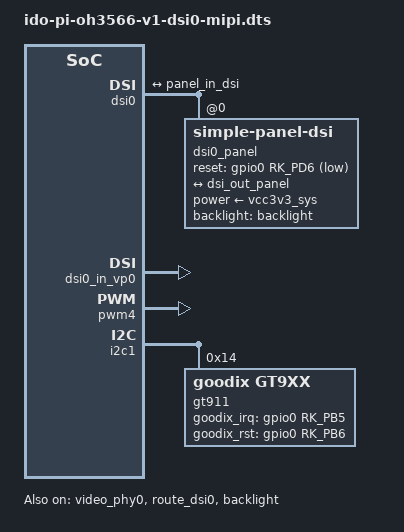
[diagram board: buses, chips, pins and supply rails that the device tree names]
// SPDX-License-Identifier: (GPL-2.0+ OR MIT)
/*
 * Copyright (c) 2020 Rockchip Electronics Co., Ltd.
 *
 */

/dts-v1/;

#include "ido-pi-oh3566-v1.dtsi"

&video_phy0 {
	status = "okay";
};

/*
 * video_phy0 needs to be enabled
 * when dsi0 is enabled
 */
&dsi0 {
	status = "okay";
	//rockchip,lane-rate = <1000>;
	dsi0_panel: panel@0 {
		status = "okay";
		compatible = "simple-panel-dsi";
		reg = <0>;
		backlight = <&backlight>;
		reset-delay-ms = <60>;
		enable-delay-ms = <60>;
		prepare-delay-ms = <60>;
		init-delay-ms = <60>;
		unprepare-delay-ms = <60>;
		disable-delay-ms = <60>;
		dsi,flags = <(MIPI_DSI_MODE_VIDEO | MIPI_DSI_MODE_VIDEO_BURST |
			MIPI_DSI_MODE_LPM | MIPI_DSI_MODE_EOT_PACKET)>;
		dsi,format = <MIPI_DSI_FMT_RGB888>;
		dsi,lanes  = <4>;
		panel-init-sequence = [
			29 00 04 FF 98 81 03 
			29 00 02 01 00 
			29 00 02 02 00 
			29 00 02 03 73 
			29 00 02 04 13 
			29 00 02 05 00 
			29 00 02 06 0A 
			29 00 02 07 05 
			29 00 02 08 00 
			29 00 02 09 28 
			29 00 02 0a 00 
			29 00 02 0b 00 
			29 00 02 0c 00 
			29 00 02 0d 28 
			29 00 02 0e 00 
			29 00 02 0f 28 
			29 00 02 10 28 
			29 00 02 11 00 
			29 00 02 12 00 
			29 00 02 13 00 
			29 00 02 14 00 
			29 00 02 15 00 
			29 00 02 16 00 
			29 00 02 17 00 
			29 00 02 18 00 
			29 00 02 19 00 
			29 00 02 1a 00 
			29 00 02 1b 00 
			29 00 02 1c 00 
			29 00 02 1d 00 
			29 00 02 1e 40 
			29 00 02 1f 80 
			29 00 02 20 06 
			29 00 02 21 01 
			29 00 02 22 00 
			29 00 02 23 00 
			29 00 02 24 00 
			29 00 02 25 00 
			29 00 02 26 00 
			29 00 02 27 00 
			29 00 02 28 33 
			29 00 02 29 33 
			29 00 02 2a 00 
			29 00 02 2b 00 
			29 00 02 2c 04 
			29 00 02 2d 04 
			29 00 02 2e 05 
			29 00 02 2f 05 
			29 00 02 30 00 
			29 00 02 31 00 
			29 00 02 32 31 
			29 00 02 33 00 
			29 00 02 34 00 
			29 00 02 35 0A 
			29 00 02 36 00 
			29 00 02 37 08 
			29 00 02 38 00 
			29 00 02 39 00 
			29 00 02 3a 00 
			29 00 02 3b 00 
			29 00 02 3c 00 
			29 00 02 3d 00 
			29 00 02 3e 00 
			29 00 02 3f 00 
			29 00 02 40 00 
			29 00 02 41 00 
			29 00 02 42 00 
			29 00 02 43 08 
			29 00 02 44 00 
			29 00 02 50 01 
			29 00 02 51 23 
			29 00 02 52 44 
			29 00 02 53 67 
			29 00 02 54 89 
			29 00 02 55 ab 
			29 00 02 56 01 
			29 00 02 57 23 
			29 00 02 58 45 
			29 00 02 59 67 
			29 00 02 5a 89 
			29 00 02 5b ab 
			29 00 02 5c cd 
			29 00 02 5d ef 
			29 00 02 5e 11 
			29 00 02 5f 02 
			29 00 02 60 08 
			29 00 02 61 0E 
			29 00 02 62 0F 
			29 00 02 63 0C 
			29 00 02 64 0D 
			29 00 02 65 17 
			29 00 02 66 01 
			29 00 02 67 01 
			29 00 02 68 02 
			29 00 02 69 02 
			29 00 02 6a 00 
			29 00 02 6b 00 
			29 00 02 6c 02 
			29 00 02 6d 02 
			29 00 02 6e 16 
			29 00 02 6f 16 
			29 00 02 70 06 
			29 00 02 71 06 
			29 00 02 72 07 
			29 00 02 73 07 
			29 00 02 74 02 
			29 00 02 75 02 
			29 00 02 76 08 
			29 00 02 77 0E 
			29 00 02 78 0F 
			29 00 02 79 0C 
			29 00 02 7a 0D 
			29 00 02 7b 17 
			29 00 02 7c 01 
			29 00 02 7d 01 
			29 00 02 7e 02 
			29 00 02 7f 02 
			29 00 02 80 00 
			29 00 02 81 00 
			29 00 02 82 02 
			29 00 02 83 02 
			29 00 02 84 16 
			29 00 02 85 16 
			29 00 02 86 06 
			29 00 02 87 06 
			29 00 02 88 07 
			29 00 02 89 07 
			29 00 02 8A 02 
			29 00 04 FF 98 81 04 
			29 00 02 6E 1A 
			29 00 02 6F 37 
			29 00 02 3A A4 
			29 00 02 8D 1F 
			29 00 02 87 BA 
			29 00 02 B2 D1 
			29 00 02 88 0B 
			29 00 02 38 01 
			29 00 02 39 00 
			29 00 02 B5 02 
			29 00 02 31 25 
			29 00 02 3B 98 
			29 00 04 FF 98 81 01 
			29 00 02 22 0A 
			29 00 02 31 00 
			29 00 02 53 5A 
			29 00 02 55 3D 
			29 00 02 50 9E 
			29 00 02 51 99 
			29 00 02 60 06 
			29 00 02 62 20 
			29 00 02 A0 00 
			29 00 02 A1 17 
			29 00 02 A2 26 
			29 00 02 A3 13 
			29 00 02 A4 16 
			29 00 02 A5 29 
			29 00 02 A6 1E 
			29 00 02 A7 1F 
			29 00 02 A8 8B 
			29 00 02 A9 1D 
			29 00 02 AA 2A 
			29 00 02 AB 7B 
			29 00 02 AC 1A 
			29 00 02 AD 19 
			29 00 02 AE 4E 
			29 00 02 AF 24 
			29 00 02 B0 29 
			29 00 02 B1 4F 
			29 00 02 B2 5C 
			29 00 02 B3 23 
			29 00 02 C0 00 
			29 00 02 C1 17 
			29 00 02 C2 26 
			29 00 02 C3 13 
			29 00 02 C4 16 
			29 00 02 C5 29 
			29 00 02 C6 1E 
			29 00 02 C7 1F 
			29 00 02 C8 8B 
			29 00 02 C9 1D 
			29 00 02 CA 2A 
			29 00 02 CB 7B 
			29 00 02 CC 1A 
			29 00 02 CD 19 
			29 00 02 CE 4E 
			29 00 02 CF 24 
			29 00 02 D0 29 
			29 00 02 D1 4F 
			29 00 02 D2 5C 
			29 00 02 D3 23
			29 00 04 FF 98 81 00 
			29 00 02 35 00
			05 78 01 11
			05 14 01 29
		];

		panel-exit-sequence = [
			05 00 01 28
			05 78 01 10
		];

		disp_timings0: display-timings {
			native-mode = <&dsi0_timing2>;
			dsi0_timing0: timing0 {
				clock-frequency = <148000000>;
				hactive = <1200>;
				vactive = <1920>;
				hback-porch = <130>;	
				hfront-porch = <160>;
				vback-porch = <16>;
				vfront-porch = <16>;
				hsync-len = <4>;
				vsync-len = <2>;
				hsync-active = <0>;
				vsync-active = <0>;
				de-active = <0>;
				pixelclk-active = <0>;
			};
			dsi0_timing1: timing1 {
				clock-frequency = <132000000>;
				hactive = <1080>;
				vactive = <1920>;
				hfront-porch = <15>;
				hsync-len = <2>;
				hback-porch = <30>;
				vfront-porch = <15>;
				vsync-len = <2>;
				vback-porch = <15>;
				hsync-active = <0>;
				vsync-active = <0>;
				de-active = <0>;
				pixelclk-active = <1>;
			};
			dsi0_timing2: timing2 {
				clock-frequency = <73400000>;
				hactive = <800>;
				vactive = <1280>;
				hfront-porch = <52>;
				hsync-len = <4>;
				hback-porch = <12>;
				vfront-porch = <60>;
				vsync-len = <18>;
				vback-porch = <50>;
				hsync-active = <0>;
				vsync-active = <0>;
				de-active = <0>;
				pixelclk-active = <1>;
			};
		};

		ports {
			#address-cells = <1>;
			#size-cells = <0>;

			port@0 {
				reg = <0>;
				panel_in_dsi: endpoint {
					remote-endpoint = <&dsi_out_panel>;
				};
			};
		};
	};

	ports {
		#address-cells = <1>;
		#size-cells = <0>;

		port@1 {
			reg = <1>;
			dsi_out_panel: endpoint {
				remote-endpoint = <&panel_in_dsi>;
			};
		};
	};

};

&dsi0_in_vp0 {
	status = "okay";
};

&dsi0_in_vp1 {
	status = "disabled";
};

&dsi0_panel {
	power-supply = <&vcc3v3_sys>;
	reset-gpios = <&gpio0 RK_PD6 GPIO_ACTIVE_LOW>;
	pinctrl-names = "default";
	pinctrl-0 = <&lcd0_rst_gpio>;
};

&route_dsi0 {
	status = "okay";
	connect = <&vp0_out_dsi0>;
};

&pwm4 {
	status = "okay";
};

&backlight {
	status = "okay";
	pwms = <&pwm4 0 25000 0>;
	default-brightness-level = <250>;
};

&hdmi {
	status = "disabled";
};

&hdmi_in_vp0 {
	status = "disabled";
};

&hdmi_in_vp1 {
	status = "disabled";
};

&hdmi_sound {
	status = "disabled";
};

&route_hdmi {
	status = "disabled";
	connect = <&vp0_out_hdmi>;
};

&i2c1 {
	status = "okay";

	gt911@14 {
		compatible = "goodix,gt9xx";
		reg = <0x14>;
		pinctrl-names = "default";
		pinctrl-0 = <&touch_gpio>;
		goodix_irq_gpio = <&gpio0 RK_PB5 IRQ_TYPE_LEVEL_LOW>;
		goodix_rst_gpio = <&gpio0 RK_PB6 GPIO_ACTIVE_HIGH>;
		touchscreen-inverted-y;
		touchscreen-swapped-x-y;
		status = "okay";
	};
};
